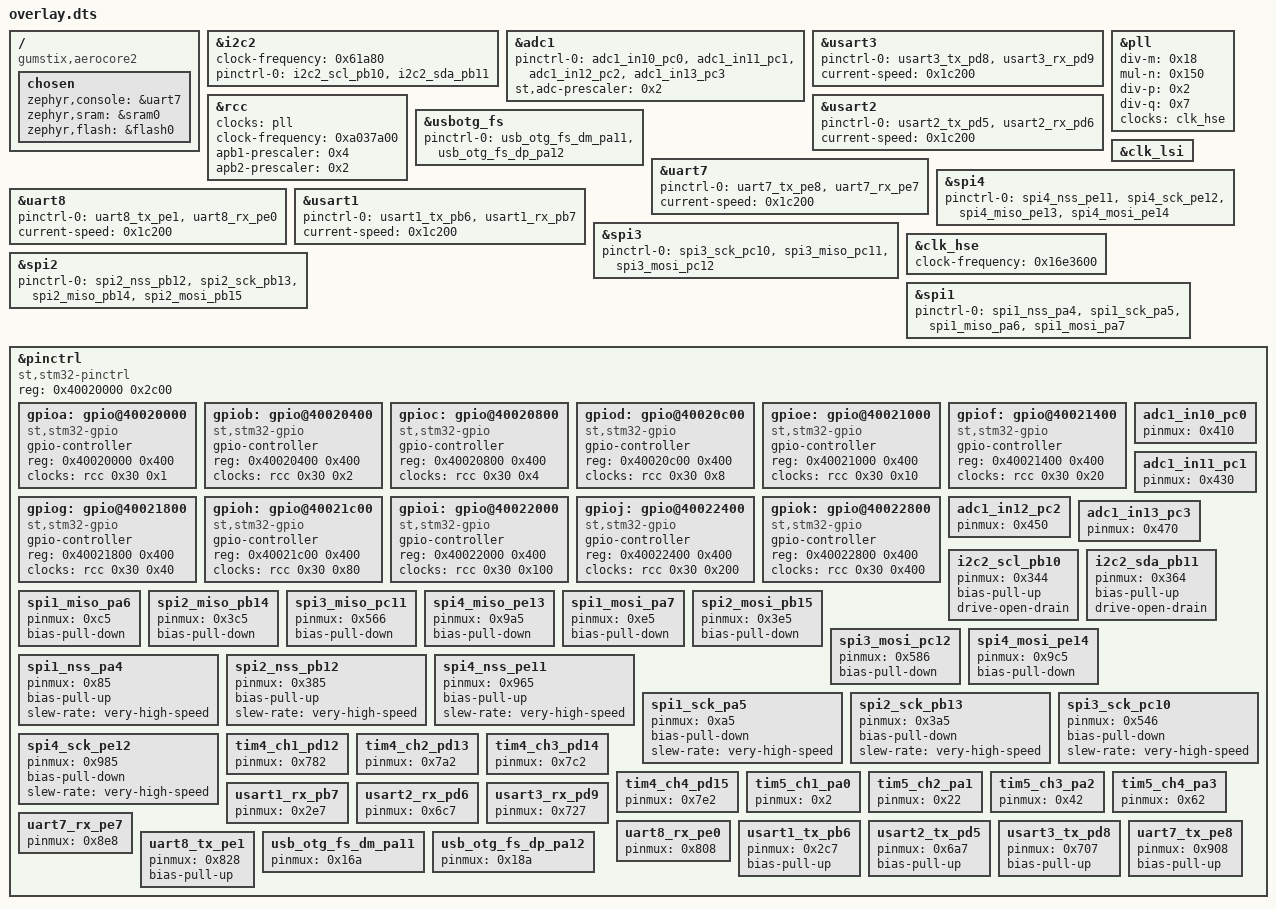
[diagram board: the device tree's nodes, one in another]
/ {
	compatible = "gumstix,aerocore2";
	chosen {
		zephyr,console = &uart7;
		zephyr,sram = &sram0;
		zephyr,flash = &flash0;
	};
};
&i2c2{
	clock-frequency = < 0x61a80 >;
	status = "okay";
	pinctrl-0 = < &i2c2_scl_pb10 &i2c2_sda_pb11 >;
	pinctrl-names = "default";
};
&adc1{
	status = "okay";
	pinctrl-0 = < &adc1_in10_pc0 &adc1_in11_pc1 &adc1_in12_pc2 &adc1_in13_pc3 >;
	pinctrl-names = "default";
	st,adc-prescaler = < 0x2 >;
};
&usart3{
	status = "okay";
	pinctrl-0 = < &usart3_tx_pd8 &usart3_rx_pd9 >;
	pinctrl-names = "default";
	current-speed = < 0x1c200 >;
};
&rcc{
	clocks = < &pll >;
	clock-frequency = < 0xa037a00 >;
	apb1-prescaler = < 0x4 >;
	apb2-prescaler = < 0x2 >;
};
&usart2{
	status = "okay";
	pinctrl-0 = < &usart2_tx_pd5 &usart2_rx_pd6 >;
	pinctrl-names = "default";
	current-speed = < 0x1c200 >;
};
&usbotg_fs{
	status = "okay";
	pinctrl-0 = < &usb_otg_fs_dm_pa11 &usb_otg_fs_dp_pa12 >;
	pinctrl-names = "default";
};
&uart7{
	status = "okay";
	pinctrl-0 = < &uart7_tx_pe8 &uart7_rx_pe7 >;
	pinctrl-names = "default";
	current-speed = < 0x1c200 >;
};
&pll{
	status = "okay";
	div-m = < 0x18 >;
	mul-n = < 0x150 >;
	div-p = < 0x2 >;
	div-q = < 0x7 >;
	clocks = < &clk_hse >;
};
&clk_lsi{
	status = "okay";
};
&spi4{
	status = "okay";
	pinctrl-0 = < &spi4_nss_pe11 &spi4_sck_pe12 &spi4_miso_pe13 &spi4_mosi_pe14 >;
	pinctrl-names = "default";
};
&uart8{
	status = "okay";
	pinctrl-0 = < &uart8_tx_pe1 &uart8_rx_pe0 >;
	pinctrl-names = "default";
	current-speed = < 0x1c200 >;
};
&usart1{
	status = "okay";
	pinctrl-0 = < &usart1_tx_pb6 &usart1_rx_pb7 >;
	pinctrl-names = "default";
	current-speed = < 0x1c200 >;
};
&spi3{
	status = "okay";
	pinctrl-0 = < &spi3_sck_pc10 &spi3_miso_pc11 &spi3_mosi_pc12 >;
	pinctrl-names = "default";
};
&clk_hse{
	status = "okay";
	clock-frequency = < 0x16e3600 >;
};
&spi2{
	status = "okay";
	pinctrl-0 = < &spi2_nss_pb12 &spi2_sck_pb13 &spi2_miso_pb14 &spi2_mosi_pb15 >;
	pinctrl-names = "default";
};
&spi1{
	status = "okay";
	pinctrl-0 = < &spi1_nss_pa4 &spi1_sck_pa5 &spi1_miso_pa6 &spi1_mosi_pa7 >;
	pinctrl-names = "default";
};
&pinctrl{
	compatible = "st,stm32-pinctrl";
	#address-cells = < 0x1 >;
	#size-cells = < 0x1 >;
	reg = < 0x40020000 0x2c00 >;
	gpioa: gpio@40020000 {
		compatible = "st,stm32-gpio";
		gpio-controller;
		#gpio-cells = < 0x2 >;
		reg = < 0x40020000 0x400 >;
		clocks = < &rcc 0x30 0x1 >;
	};
	gpiob: gpio@40020400 {
		compatible = "st,stm32-gpio";
		gpio-controller;
		#gpio-cells = < 0x2 >;
		reg = < 0x40020400 0x400 >;
		clocks = < &rcc 0x30 0x2 >;
	};
	gpioc: gpio@40020800 {
		compatible = "st,stm32-gpio";
		gpio-controller;
		#gpio-cells = < 0x2 >;
		reg = < 0x40020800 0x400 >;
		clocks = < &rcc 0x30 0x4 >;
	};
	gpiod: gpio@40020c00 {
		compatible = "st,stm32-gpio";
		gpio-controller;
		#gpio-cells = < 0x2 >;
		reg = < 0x40020c00 0x400 >;
		clocks = < &rcc 0x30 0x8 >;
	};
	gpioe: gpio@40021000 {
		compatible = "st,stm32-gpio";
		gpio-controller;
		#gpio-cells = < 0x2 >;
		reg = < 0x40021000 0x400 >;
		clocks = < &rcc 0x30 0x10 >;
	};
	gpiof: gpio@40021400 {
		compatible = "st,stm32-gpio";
		gpio-controller;
		#gpio-cells = < 0x2 >;
		reg = < 0x40021400 0x400 >;
		clocks = < &rcc 0x30 0x20 >;
	};
	gpiog: gpio@40021800 {
		compatible = "st,stm32-gpio";
		gpio-controller;
		#gpio-cells = < 0x2 >;
		reg = < 0x40021800 0x400 >;
		clocks = < &rcc 0x30 0x40 >;
	};
	gpioh: gpio@40021c00 {
		compatible = "st,stm32-gpio";
		gpio-controller;
		#gpio-cells = < 0x2 >;
		reg = < 0x40021c00 0x400 >;
		clocks = < &rcc 0x30 0x80 >;
	};
	gpioi: gpio@40022000 {
		compatible = "st,stm32-gpio";
		gpio-controller;
		#gpio-cells = < 0x2 >;
		reg = < 0x40022000 0x400 >;
		clocks = < &rcc 0x30 0x100 >;
	};
	gpioj: gpio@40022400 {
		compatible = "st,stm32-gpio";
		gpio-controller;
		#gpio-cells = < 0x2 >;
		reg = < 0x40022400 0x400 >;
		clocks = < &rcc 0x30 0x200 >;
	};
	gpiok: gpio@40022800 {
		compatible = "st,stm32-gpio";
		gpio-controller;
		#gpio-cells = < 0x2 >;
		reg = < 0x40022800 0x400 >;
		clocks = < &rcc 0x30 0x400 >;
	};
	adc1_in10_pc0: adc1_in10_pc0 {
		pinmux = < 0x410 >;
	};
	adc1_in11_pc1: adc1_in11_pc1 {
		pinmux = < 0x430 >;
	};
	adc1_in12_pc2: adc1_in12_pc2 {
		pinmux = < 0x450 >;
	};
	adc1_in13_pc3: adc1_in13_pc3 {
		pinmux = < 0x470 >;
	};
	i2c2_scl_pb10: i2c2_scl_pb10 {
		pinmux = < 0x344 >;
		bias-pull-up;
		drive-open-drain;
	};
	i2c2_sda_pb11: i2c2_sda_pb11 {
		pinmux = < 0x364 >;
		bias-pull-up;
		drive-open-drain;
	};
	spi1_miso_pa6: spi1_miso_pa6 {
		pinmux = < 0xc5 >;
		bias-pull-down;
	};
	spi2_miso_pb14: spi2_miso_pb14 {
		pinmux = < 0x3c5 >;
		bias-pull-down;
	};
	spi3_miso_pc11: spi3_miso_pc11 {
		pinmux = < 0x566 >;
		bias-pull-down;
	};
	spi4_miso_pe13: spi4_miso_pe13 {
		pinmux = < 0x9a5 >;
		bias-pull-down;
	};
	spi1_mosi_pa7: spi1_mosi_pa7 {
		pinmux = < 0xe5 >;
		bias-pull-down;
	};
	spi2_mosi_pb15: spi2_mosi_pb15 {
		pinmux = < 0x3e5 >;
		bias-pull-down;
	};
	spi3_mosi_pc12: spi3_mosi_pc12 {
		pinmux = < 0x586 >;
		bias-pull-down;
	};
	spi4_mosi_pe14: spi4_mosi_pe14 {
		pinmux = < 0x9c5 >;
		bias-pull-down;
	};
	spi1_nss_pa4: spi1_nss_pa4 {
		pinmux = < 0x85 >;
		bias-pull-up;
		slew-rate = "very-high-speed";
	};
	spi2_nss_pb12: spi2_nss_pb12 {
		pinmux = < 0x385 >;
		bias-pull-up;
		slew-rate = "very-high-speed";
	};
	spi4_nss_pe11: spi4_nss_pe11 {
		pinmux = < 0x965 >;
		bias-pull-up;
		slew-rate = "very-high-speed";
	};
	spi1_sck_pa5: spi1_sck_pa5 {
		pinmux = < 0xa5 >;
		bias-pull-down;
		slew-rate = "very-high-speed";
	};
	spi2_sck_pb13: spi2_sck_pb13 {
		pinmux = < 0x3a5 >;
		bias-pull-down;
		slew-rate = "very-high-speed";
	};
	spi3_sck_pc10: spi3_sck_pc10 {
		pinmux = < 0x546 >;
		bias-pull-down;
		slew-rate = "very-high-speed";
	};
	spi4_sck_pe12: spi4_sck_pe12 {
		pinmux = < 0x985 >;
		bias-pull-down;
		slew-rate = "very-high-speed";
	};
	tim4_ch1_pd12: tim4_ch1_pd12 {
		pinmux = < 0x782 >;
	};
	tim4_ch2_pd13: tim4_ch2_pd13 {
		pinmux = < 0x7a2 >;
	};
	tim4_ch3_pd14: tim4_ch3_pd14 {
		pinmux = < 0x7c2 >;
	};
	tim4_ch4_pd15: tim4_ch4_pd15 {
		pinmux = < 0x7e2 >;
	};
	tim5_ch1_pa0: tim5_ch1_pa0 {
		pinmux = < 0x2 >;
	};
	tim5_ch2_pa1: tim5_ch2_pa1 {
		pinmux = < 0x22 >;
	};
	tim5_ch3_pa2: tim5_ch3_pa2 {
		pinmux = < 0x42 >;
	};
	tim5_ch4_pa3: tim5_ch4_pa3 {
		pinmux = < 0x62 >;
	};
	usart1_rx_pb7: usart1_rx_pb7 {
		pinmux = < 0x2e7 >;
	};
	usart2_rx_pd6: usart2_rx_pd6 {
		pinmux = < 0x6c7 >;
	};
	usart3_rx_pd9: usart3_rx_pd9 {
		pinmux = < 0x727 >;
	};
	uart7_rx_pe7: uart7_rx_pe7 {
		pinmux = < 0x8e8 >;
	};
	uart8_rx_pe0: uart8_rx_pe0 {
		pinmux = < 0x808 >;
	};
	usart1_tx_pb6: usart1_tx_pb6 {
		pinmux = < 0x2c7 >;
		bias-pull-up;
	};
	usart2_tx_pd5: usart2_tx_pd5 {
		pinmux = < 0x6a7 >;
		bias-pull-up;
	};
	usart3_tx_pd8: usart3_tx_pd8 {
		pinmux = < 0x707 >;
		bias-pull-up;
	};
	uart7_tx_pe8: uart7_tx_pe8 {
		pinmux = < 0x908 >;
		bias-pull-up;
	};
	uart8_tx_pe1: uart8_tx_pe1 {
		pinmux = < 0x828 >;
		bias-pull-up;
	};
	usb_otg_fs_dm_pa11: usb_otg_fs_dm_pa11 {
		pinmux = < 0x16a >;
	};
	usb_otg_fs_dp_pa12: usb_otg_fs_dp_pa12 {
		pinmux = < 0x18a >;
	};
};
